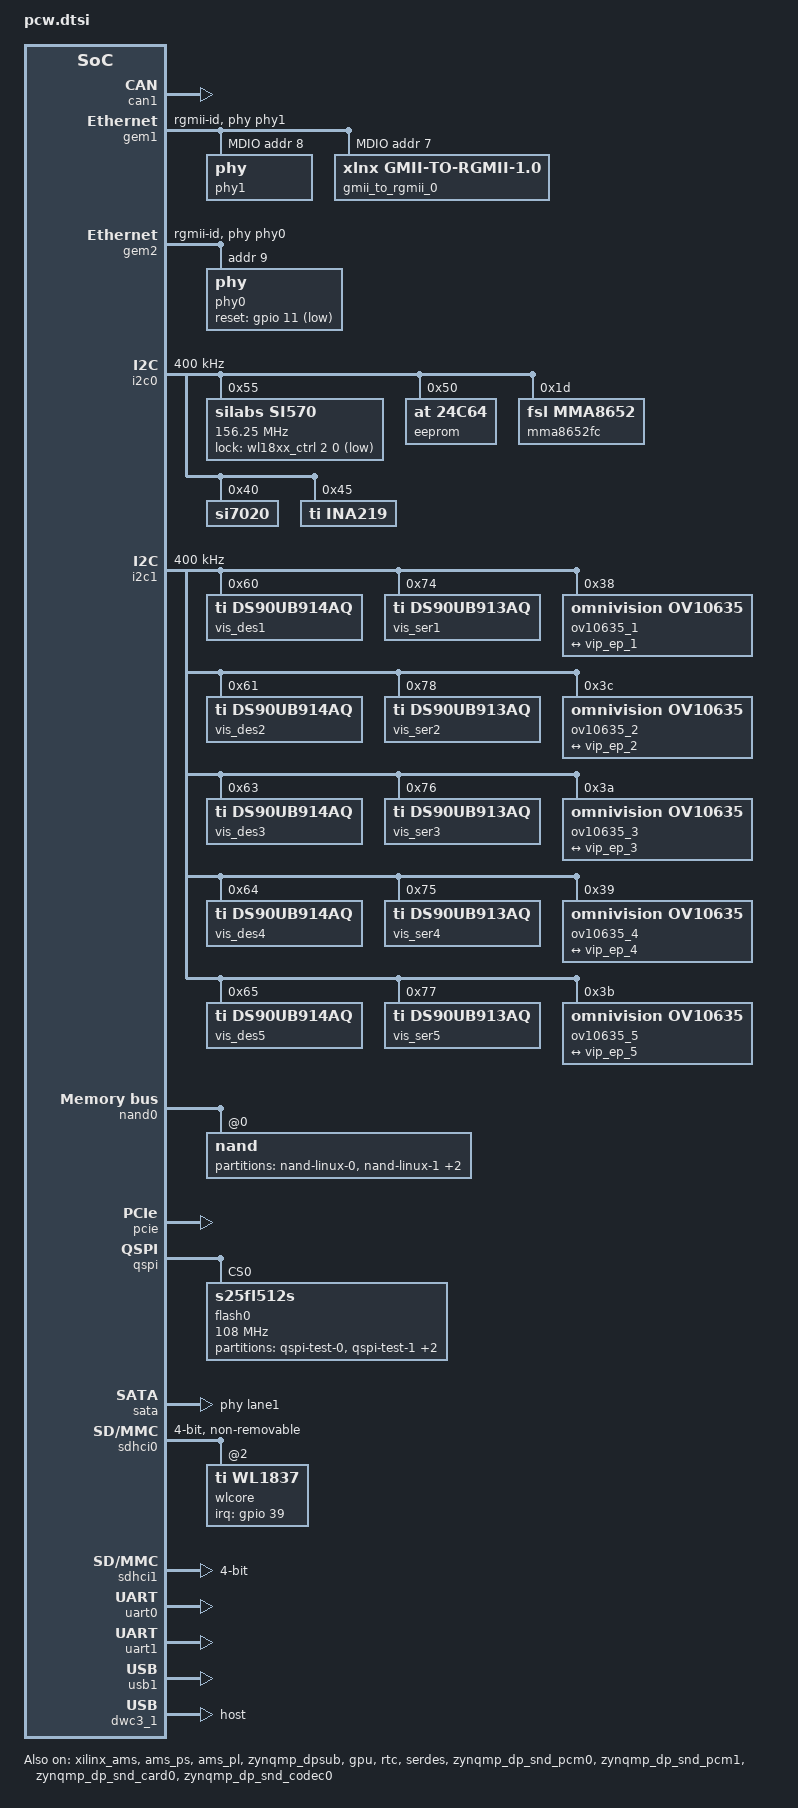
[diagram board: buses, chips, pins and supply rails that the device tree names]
/*
 * CAUTION: This file is automatically generated by Xilinx.
 * Version:  
 * Today is: Tue Oct 23 14:24:34 2018
 */


&lpd_dma_chan1 {
	status = "okay";
};
&lpd_dma_chan2 {
	status = "okay";
};
&lpd_dma_chan3 {
	status = "okay";
};
&lpd_dma_chan4 {
	status = "okay";
};
&lpd_dma_chan5 {
	status = "okay";
};
&lpd_dma_chan6 {
	status = "okay";
};
&lpd_dma_chan7 {
	status = "okay";
};
&lpd_dma_chan8 {
	status = "okay";
};
&xilinx_ams {
	status = "okay";
};
&ams_ps {
	status = "okay";
};
&ams_pl {
	status = "okay";
	xlnx,ext-channels {
		#address-cells = <1>;
		#size-cells = <0>;
		channel@0 {
			reg = <0>;
			xlnx,bipolar;
		};
	};
};
&perf_monitor_ocm {
	xlnx,enable-32bit-filter-id = <0x1>;
	xlnx,enable-advanced = <0x1>;
	xlnx,enable-event-count = <0x1>;
	xlnx,enable-event-log = <0x0>;
	xlnx,enable-profile = <0x0>;
	xlnx,enable-trace = <0x0>;
	xlnx,fifo-axis-depth = <0x20>;
	xlnx,fifo-axis-tdata-width = <0x38>;
	xlnx,fifo-axis-tid-width = <0x1>;
	xlnx,global-count-width = <0x20>;
	xlnx,have-sampled-metric-cnt = <0x1>;
	xlnx,metric-count-scale = <0x1>;
	xlnx,metrics-sample-count-width = <0x20>;
	xlnx,num-monitor-slots = <0x1>;
	xlnx,num-of-counters = <0x3>;
};
&can1 {
	status = "okay";
};
&zynqmp_dpsub {
	phy-names = "dp-phy0","dp-phy1";
	phys = <&lane3 5 0 2 135000000>,
		<&lane2 5 1 2 135000000>;
	status = "okay";
	xlnx,max-lanes = <2>;
};
&xlnx_dpdma {
	status = "okay";
};
&gem1 {
    phy-mode = "rgmii-id";
    status = "okay";
    xlnx,ptp-enet-clock = <0x0>;
    phy-reset-gpio = <&ETH1_RESET_n 0 0 1>;
    phy-reset-duration = <2>;
    phy-reset-active-low;
    phy-handle = <&phy1>;
    gmii2rgmii-phy-handle = <&gmii_to_rgmii_0>;
	local-mac-address = [00 0a 35 3a 02 00];
    ps7_ethernet_1_mdio: mdio {
        #address-cells = <1>;
        #size-cells = <0>;
        phy1: phy@8 {
            device_type = "ethernet-phy";
            reg = <8>;
            ti,rx-internal-delay = <0x8>;
            ti,tx-internal-delay = <0xa>;
            ti,fifo-depth = <0x1>;
        };
        gmii_to_rgmii_0: phy@7 {
			device_type = "ethernet-phy";
            compatible = "xlnx,gmii-to-rgmii-1.0";
            reg = <7>;
            phy-handle = <&phy1>;
        };
    };
};
&gem2 {
    status = "okay";
    phy-handle = <&phy0>;
    phy-mode = "rgmii-id";
    //phy-reset-gpio = <&gpio 11 1>;
    phy-reset-duration = <2>;
    phy-reset-active-low;
    local-mac-address = [00 0a 35 3a 02 01];
    phy0: phy@9 {
        device_type = "ethernet-phy";
        reg = <0x9>;
        ti,rx-internal-delay = <0x8>;
        ti,tx-internal-delay = <0xa>;
        ti,fifo-depth = <0x1>;
        ti,rxctrl-strap-worka;
		reset-gpios = <&gpio 11 1>;
    };
};
&fpd_dma_chan1 {
	status = "okay";
};
&fpd_dma_chan2 {
	status = "okay";
};
&fpd_dma_chan3 {
	status = "okay";
};
&fpd_dma_chan4 {
	status = "okay";
};
&fpd_dma_chan5 {
	status = "okay";
};
&fpd_dma_chan6 {
	status = "okay";
};
&fpd_dma_chan7 {
	status = "okay";
};
&fpd_dma_chan8 {
	status = "okay";
};
&gpio {
	emio-gpio-width = <96>;
	gpio-mask-high = <0x0>;
	gpio-mask-low = <0x5600>;
	status = "okay";
};
&gpu {
	status = "okay";
};
&i2c0 {
	clock-frequency = <400000>;
	status = "okay";
	si570: clock-generator@55 {
		#clock-cells = <0>;
		compatible = "silabs,si570";
		reg = <0x55>;
		temperature-stability = <50>;
		factory-fout = <156250000>;
		clock-frequency = <156250000>;
		lock-gpios = <&wl18xx_ctrl 2 0 1>;
	};
	
	eeprom@50 {
                compatible = "at,24c64";
                reg = <0x50>;
        };
	
	mma8652fc@1d {
		compatible = "fsl,mma8652";
		reg = <0x1d>;
	};	
	
	si7020@40 {
                compatible = "si7020";
                reg = <0x40>;
        };
	
	ina219@45 {
		compatible = "ti,ina219";
		reg = <0x45>;
		shunt-resistor = <2000>;
	};
};
&i2c1 {
	status = "okay";
	clock-frequency = <400000>;

	vis_des1: ds90ub914aq@60 {
		compatible = "ti,ds90ub914aq";
		reg = <0x60>;
	};
	vis_ser1: ds90ub913aq@74 {
		compatible = "ti,ds90ub913aq";
		reg = <0x74>;
	};
	ov10635_1: ov10635@38 {
		compatible = "omnivision,ov10635";
		reg = <0x38>;
		deserializer = <&vis_des1>;
		serializer = <&vis_ser1>;

		port {
			ov10635_ep_1: endpoint {
				remote-endpoint = <&vip_ep_1>;      
			};
		};
	};
	
	vis_des2: ds90ub914aq@61 {
		compatible = "ti,ds90ub914aq";
		reg = <0x61>;
	};
	vis_ser2: ds90ub913aq@78 {
		compatible = "ti,ds90ub913aq";
		reg = <0x78>;
	};
	ov10635_2: ov10635@3C {
		compatible = "omnivision,ov10635";
		reg = <0x3C>;
		deserializer = <&vis_des2>;
		serializer = <&vis_ser2>;

		port {
			ov10635_ep_2: endpoint {
				remote-endpoint = <&vip_ep_2>;      
			};
		};
	};
	
	vis_des3: ds90ub914aq@63 {
		compatible = "ti,ds90ub914aq";
		reg = <0x63>;
	};
	vis_ser3: ds90ub913aq@76 {
		compatible = "ti,ds90ub913aq";
		reg = <0x76>;
	};
	ov10635_3: ov10635@3A {
		compatible = "omnivision,ov10635";
		reg = <0x3A>;
		deserializer = <&vis_des3>;
		serializer = <&vis_ser3>;

		port {
			ov10635_ep_3: endpoint {
				remote-endpoint = <&vip_ep_3>;      
			};
		};
	};
	
	vis_des4: ds90ub914aq@64 {
		compatible = "ti,ds90ub914aq";
		reg = <0x64>;
	};
	vis_ser4: ds90ub913aq@75 {
		compatible = "ti,ds90ub913aq";
		reg = <0x75>;
	};
	ov10635_4: ov10635@39 {
		compatible = "omnivision,ov10635";
		reg = <0x39>;
		deserializer = <&vis_des4>;
		serializer = <&vis_ser4>;

		port {
			ov10635_ep_4: endpoint {
				remote-endpoint = <&vip_ep_4>;      
			};
		};
	};
	
	vis_des5: ds90ub914aq@65 {
		compatible = "ti,ds90ub914aq";
		reg = <0x65>;
	};

	vis_ser5: ds90ub913aq@77 {
		compatible = "ti,ds90ub913aq";
		reg = <0x77>;
	};
	ov10635_5: ov10635@3B {
		compatible = "omnivision,ov10635";
		reg = <0x3B>;
		deserializer = <&vis_des5>;
		serializer = <&vis_ser5>;

		port {
			ov10635_ep_5: endpoint {
				remote-endpoint = <&vip_ep_5>;      
			};
		};
	};
};
&pinctrl0 {
	status = "okay";
};
&nand0 {
	status = "okay";
	arasan,has-mdma;
	num-cs = <1>;

	nand@0 {
		reg = <0x0>;
		#address-cells = <0x1>;
		#size-cells = <0x1>;
		
		partition@nand-linux-0 { /* test purposes */
			label = "nand-linux-0";
			reg = <0x00000000 0x04000000>;
		};
		partition@nand-linux-1 { /* test purposes */
			label = "nand-linux-1";
			reg = <0x04000000 0x04000000>;
		};
		partition@nand-linux-2 { /* test purposes */
			label = "nand-linux-2";
			reg = <0x08000000 0x04000000>;
		};
		partition@nand-linux-3 { /* test purposes */
			label = "nand-linux-3";
			reg = <0x0C000000 0x04000000>;
		};
	};
};
&pcie {
	status = "okay";
	xlnx,pcie-mode = "Root Port";
};
&qspi {
	is-dual = <0>;
	num-cs = <1>;
	status = "okay";
	
	flash0: flash@0 {
		compatible = "s25fl512s";
		spi-tx-bus-width=<1>;
		spi-rx-bus-width=<4>;
		reg = <0x0>;
		#address-cells = <1>;
		#size-cells = <1>;
		spi-max-frequency = <108000000>;
		
		partition@test-0 { /* test purposes */
			label = "qspi-test-0";
			reg = <0x00000000 0x01000000>;
		};
		partition@test-1 { /* test purposes */
			label = "qspi-test-1";
			reg = <0x01000000 0x01000000>;
		};
		partition@test-2 { /* test purposes */
			label = "qspi-test-2";
			reg = <0x02000000 0x01000000>;
		};
		partition@test-3 { /* test purposes */
			label = "qspi-test-3";
			reg = <0x03000000 0x01000000>;
		};
	};
};
&rtc {
	status = "okay";
};
&sata {
	status = "okay";
	phy-names = "sata-phy";
	phys = <&lane1 1 1 1 150000000>;
	ceva,p0-burst-params = /bits/ 8 <0x13 0x08 0x4A 0x06>;
	ceva,p0-cominit-params = /bits/ 8 <0x18 0x40 0x18 0x28>;
	ceva,p0-comwake-params = /bits/ 8 <0x06 0x14 0x08 0x0E>;
	ceva,p0-retry-params = /bits/ 16 <0x96A4 0x3FFC>;
	ceva,p1-burst-params = /bits/ 8 <0x13 0x08 0x4A 0x06>;
	ceva,p1-cominit-params = /bits/ 8 <0x18 0x40 0x18 0x28>;
	ceva,p1-comwake-params = /bits/ 8 <0x06 0x14 0x08 0x0E>;
	ceva,p1-retry-params = /bits/ 16 <0x96A4 0x3FFC>;
	/delete-property/iommus;
};
&sdhci0 {
	clock-frequency = <50000000>;
	status = "okay";
	no-1-8-v;
	bus-width = <4>;
	broken-cd;
	xlnx,mio_bank = <1>;
	disable-wp;
	non-removable;
	enable-sdio-wakeup;
	mmc-pwrseq = <&sdio_pwrseq>;
	vqmmc-supply = <&wmmcsdio_fixed>;
	ti,non-removable;
	ti,needs-special-hs-handling;
	cap-power-off-card;
	keep-power-in-suspend;
	
	#address-cells = <1>;
	#size-cells = <0>;
	wlcore: wlcore@2 {
		status = "okay";
		compatible = "ti,wl1837";
		reg = <2>;
		interrupt-parent = <&gpio>;
		interrupts = <39 1>;
	};
};
/*
&sdhci0 {
	clock-frequency = <50000000>;
	status = "okay";
	xlnx,mio_bank = <0x1>;
	no-1-8-v;
	disable-wp;
	bus-width = <4>;
};
*/
&sdhci1 {
	clock-frequency = <99999000>;
	status = "okay";
	xlnx,mio_bank = <0x1>;
	no-1-8-v;
	disable-wp;
	bus-width = <4>;
};
&serdes {
	status = "okay";
};
&uart0 {
	device_type = "serial";
	port-number = <1>;
	status = "okay";
	u-boot,dm-pre-reloc ;
};
&uart1 {
	device_type = "serial";
	port-number = <0>;
	status = "okay";
	u-boot,dm-pre-reloc ;
};
&usb1 {
	status = "okay";
	xlnx,usb-reset = <0x5>;
	/delete-property/clocks;
	/delete-property/clock-names;
	clocks = <0x3 0x21>;
	clock-names = "bus_clk";
};
&dwc3_1 {
	status = "okay";
	dr_mode = "host";
	maximum-speed = "high-speed";
	
	/delete-property/ phy-names ;
	/delete-property/ phys ;
	/delete-property/ snps,usb3_lpm_capable;
	snps,dis_u2_susphy_quirk;
	snps,dis_u3_susphy_quirk;
	snps,hsphy_interface = "ulpi";
};

&fclk0 {
	status = "okay";
};
&ams_ps {
	status = "okay";
};
&ams_pl {
	status = "okay";
};
&zynqmp_dp_snd_pcm0 {
	status = "okay";
};
&zynqmp_dp_snd_pcm1 {
	status = "okay";
};
&zynqmp_dp_snd_card0 {
	status = "okay";
};
&zynqmp_dp_snd_codec0 {
	status = "okay";
};
